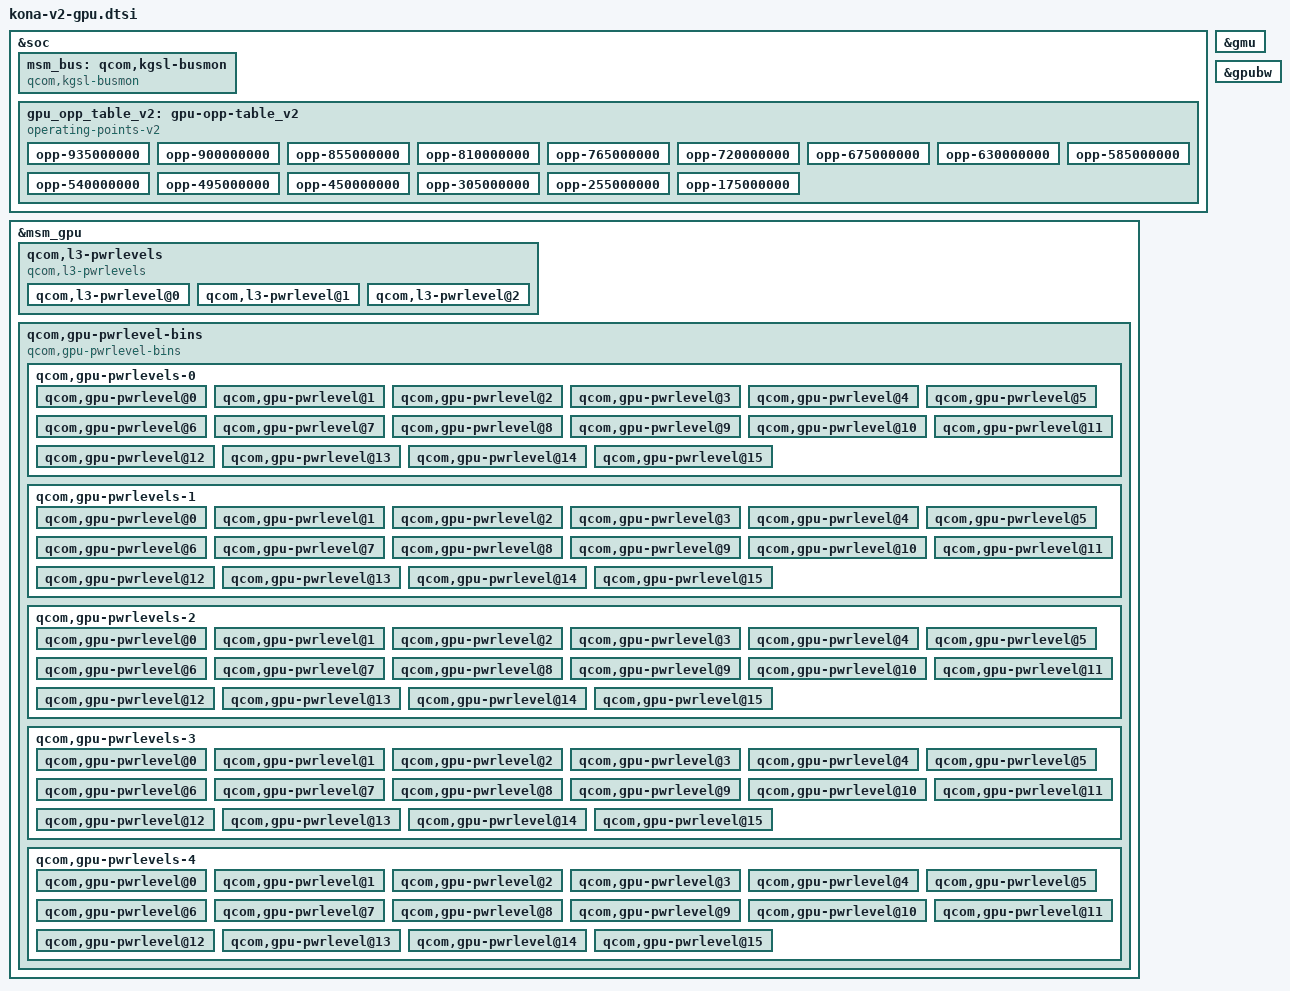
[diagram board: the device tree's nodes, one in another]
&soc {
	msm_bus: qcom,kgsl-busmon {
		label = "kgsl-busmon";
		compatible = "qcom,kgsl-busmon";
		operating-points-v2 = <&gpu_opp_table_v2>;
	};

	gpu_opp_table_v2: gpu-opp-table_v2 {
		compatible = "operating-points-v2";

		opp-935000000 {
			opp-hz = /bits/ 64 <935000000>;
			opp-microvolt = <RPMH_REGULATOR_LEVEL_TURBO_L1>;
		};

		opp-900000000 {
			opp-hz = /bits/ 64 <900000000>;
			opp-microvolt = <RPMH_REGULATOR_LEVEL_TURBO>;
		};

		opp-855000000 {
			opp-hz = /bits/ 64 <855000000>;
			opp-microvolt = <RPMH_REGULATOR_LEVEL_TURBO>;
		};

		opp-810000000 {
			opp-hz = /bits/ 64 <810000000>;
			opp-microvolt = <RPMH_REGULATOR_LEVEL_TURBO>;
		};

		opp-765000000 {
			opp-hz = /bits/ 64 <765000000>;
			opp-microvolt = <RPMH_REGULATOR_LEVEL_NOM_L2>;
		};

		opp-720000000 {
			opp-hz = /bits/ 64 <720000000>;
			opp-microvolt = <RPMH_REGULATOR_LEVEL_NOM_L2>;
		};

		opp-675000000 {
			opp-hz = /bits/ 64 <675000000>;
			opp-microvolt = <RPMH_REGULATOR_LEVEL_NOM_L1>;
		};

		opp-630000000 {
			opp-hz = /bits/ 64 <630000000>;
			opp-microvolt = <RPMH_REGULATOR_LEVEL_NOM_L1>;
		};

		opp-585000000 {
			opp-hz = /bits/ 64 <585000000>;
			opp-microvolt = <RPMH_REGULATOR_LEVEL_NOM>;
		};

		opp-540000000 {
			opp-hz = /bits/ 64 <540000000>;
			opp-microvolt = <RPMH_REGULATOR_LEVEL_NOM>;
		};

		opp-495000000 {
			opp-hz = /bits/ 64 <495000000>;
			opp-microvolt = <RPMH_REGULATOR_LEVEL_SVS_L2>;
		};

		opp-450000000 {
			opp-hz = /bits/ 64 <450000000>;
			opp-microvolt = <RPMH_REGULATOR_LEVEL_SVS_L1>;
		};

		opp-305000000 {
			opp-hz = /bits/ 64 <305000000>;
			opp-microvolt = <RPMH_REGULATOR_LEVEL_SVS>;
		};

		opp-255000000 {
			opp-hz = /bits/ 64 <255000000>;
			opp-microvolt = <RPMH_REGULATOR_LEVEL_SVS>;
		};

		opp-175000000 {
			opp-hz = /bits/ 64 <175000000>;
			opp-microvolt = <RPMH_REGULATOR_LEVEL_LOW_SVS>;
		};
	};
};

&msm_gpu {
	qcom,chipid = <0x06050001>;
	interconnects = <&kona_icc KONA_ICC_GPU_TO_LLCC>,
			<&kona_icc KONA_ICC_GPU_TO_MEM>,
			<&kona_icc KONA_ICC_CPU_TO_GPU_CFG>;
	interconnect-names = "gpu-llcc", "gpu-ddr", "cpu-gpu-cfg";

	/*
	 * Kona V2 keeps ICC BW tables explicit in this override as well so
	 * V2 targets don't depend on base include ordering for ICC-first voting.
	 */
	qcom,gpu-icc-bw-avg-kbps =
		<1 292968 440429 622558 760253 946289 1113281
		 1406250 1968750 2390625 2812500 3515625 4218750 4921875>;
	qcom,gpu-icc-bw-peak-kbps =
		<1 1171875 1761718 2490234 3041015 3785156 4453125
		 5625000 7875000 9562500 11250000 14062500 16875000 19687500>;
	qcom,gpu-cfg-icc-bw-avg-kbps = <1 25>;
	qcom,gpu-cfg-icc-bw-peak-kbps = <1 100>;

	qcom,ca-busy-penalty = <9000>;
	qcom,enable-midframe-timer;
	qcom,wakeup-boost-ms = <60>;
	qcom,wakeup-boost-pwrlevel = <4>;
	qcom,tz-sample-floor = <2500>;
	qcom,tz-min-busy = <550>;
	qcom,tz-busy-ceiling = <28000>;

	/* GPU OPP data */
	operating-points-v2 = <&gpu_opp_table_v2>;

	/delete-property/qcom,initial-pwrlevel;
	/delete-node/qcom,gpu-pwrlevels;
	/delete-node/qcom,l3-pwrlevels;

	/* L3 vote levels tuned for the higher Kona V2 GPU bins */
	qcom,l3-pwrlevels {
		#address-cells = <1>;
		#size-cells = <0>;
		compatible = "qcom,l3-pwrlevels";

		qcom,l3-pwrlevel@0 {
			reg = <0>;
			qcom,l3-freq = <0>;
		};

		qcom,l3-pwrlevel@1 {
			reg = <1>;
			qcom,l3-freq = <1066000000>;
		};

		qcom,l3-pwrlevel@2 {
			reg = <2>;
			qcom,l3-freq = <1612800000>;
		};
	};

	/* Power levels bins */
	qcom,gpu-pwrlevel-bins {
		compatible="qcom,gpu-pwrlevel-bins";
		#address-cells = <1>;
		#size-cells = <0>;

		qcom,gpu-pwrlevels-0 {
			#address-cells = <1>;
			#size-cells = <0>;
			qcom,speed-bin = <0>;
			qcom,initial-pwrlevel = <4>;
			qcom,max-pwrlevel = <1>;

					qcom,gpu-pwrlevel@0 {
								reg = <0>;
								qcom,gpu-freq = <935000000>;
								qcom,bus-freq-ddr7 = <13>;
								qcom,bus-min-ddr7 = <13>;
								qcom,bus-max-ddr7 = <13>;

								qcom,bus-freq-ddr8 = <13>;
								qcom,bus-min-ddr8 = <13>;
								qcom,bus-max-ddr8 = <13>;
							};

							qcom,gpu-pwrlevel@1 {
								reg = <1>;
								qcom,gpu-freq = <900000000>;
								qcom,bus-freq-ddr7 = <13>;
								qcom,bus-min-ddr7 = <13>;
								qcom,bus-max-ddr7 = <13>;

								qcom,bus-freq-ddr8 = <13>;
								qcom,bus-min-ddr8 = <13>;
								qcom,bus-max-ddr8 = <13>;
							};

							qcom,gpu-pwrlevel@2 {
								reg = <2>;
								qcom,gpu-freq = <855000000>;
								qcom,bus-freq-ddr7 = <13>;
								qcom,bus-min-ddr7 = <13>;
								qcom,bus-max-ddr7 = <13>;

								qcom,bus-freq-ddr8 = <13>;
								qcom,bus-min-ddr8 = <13>;
								qcom,bus-max-ddr8 = <13>;
							};

							qcom,gpu-pwrlevel@3 {
								reg = <3>;
								qcom,gpu-freq = <810000000>;
								qcom,bus-freq-ddr7 = <13>;
								qcom,bus-min-ddr7 = <13>;
								qcom,bus-max-ddr7 = <13>;

								qcom,bus-freq-ddr8 = <13>;
								qcom,bus-min-ddr8 = <13>;
								qcom,bus-max-ddr8 = <13>;
							};

							qcom,gpu-pwrlevel@4 {
								reg = <4>;
								qcom,gpu-freq = <765000000>;
								qcom,bus-freq-ddr7 = <12>;
								qcom,bus-min-ddr7 = <12>;
								qcom,bus-max-ddr7 = <12>;

								qcom,bus-freq-ddr8 = <12>;
								qcom,bus-min-ddr8 = <12>;
								qcom,bus-max-ddr8 = <12>;
							};

							qcom,gpu-pwrlevel@5 {
								reg = <5>;
								qcom,gpu-freq = <720000000>;
								qcom,bus-freq-ddr7 = <12>;
								qcom,bus-min-ddr7 = <12>;
								qcom,bus-max-ddr7 = <12>;

								qcom,bus-freq-ddr8 = <12>;
								qcom,bus-min-ddr8 = <12>;
								qcom,bus-max-ddr8 = <12>;
							};

							qcom,gpu-pwrlevel@6 {
								reg = <6>;
								qcom,gpu-freq = <675000000>;
								qcom,bus-freq-ddr7 = <11>;
								qcom,bus-min-ddr7 = <11>;
								qcom,bus-max-ddr7 = <11>;

								qcom,bus-freq-ddr8 = <11>;
								qcom,bus-min-ddr8 = <11>;
								qcom,bus-max-ddr8 = <11>;
							};

							qcom,gpu-pwrlevel@7 {
								reg = <7>;
								qcom,gpu-freq = <630000000>;
								qcom,bus-freq-ddr7 = <11>;
								qcom,bus-min-ddr7 = <11>;
								qcom,bus-max-ddr7 = <11>;

								qcom,bus-freq-ddr8 = <11>;
								qcom,bus-min-ddr8 = <11>;
								qcom,bus-max-ddr8 = <11>;
							};

							qcom,gpu-pwrlevel@8 {
								reg = <8>;
								qcom,gpu-freq = <585000000>;
								qcom,bus-freq-ddr7 = <10>;
								qcom,bus-min-ddr7 = <10>;
								qcom,bus-max-ddr7 = <10>;

								qcom,bus-freq-ddr8 = <10>;
								qcom,bus-min-ddr8 = <10>;
								qcom,bus-max-ddr8 = <10>;
							};

							qcom,gpu-pwrlevel@9 {
								reg = <9>;
								qcom,gpu-freq = <540000000>;
								qcom,bus-freq-ddr7 = <10>;
								qcom,bus-min-ddr7 = <10>;
								qcom,bus-max-ddr7 = <10>;

								qcom,bus-freq-ddr8 = <10>;
								qcom,bus-min-ddr8 = <10>;
								qcom,bus-max-ddr8 = <10>;
							};

							qcom,gpu-pwrlevel@10 {
								reg = <10>;
								qcom,gpu-freq = <495000000>;
								qcom,bus-freq-ddr7 = <9>;
								qcom,bus-min-ddr7 = <9>;
								qcom,bus-max-ddr7 = <9>;

								qcom,bus-freq-ddr8 = <9>;
								qcom,bus-min-ddr8 = <9>;
								qcom,bus-max-ddr8 = <9>;
							};

							qcom,gpu-pwrlevel@11 {
								reg = <11>;
								qcom,gpu-freq = <450000000>;
								qcom,bus-freq-ddr7 = <8>;
								qcom,bus-min-ddr7 = <8>;
								qcom,bus-max-ddr7 = <8>;

								qcom,bus-freq-ddr8 = <8>;
								qcom,bus-min-ddr8 = <8>;
								qcom,bus-max-ddr8 = <8>;
							};

							qcom,gpu-pwrlevel@12 {
								reg = <12>;
								qcom,gpu-freq = <305000000>;
								qcom,bus-freq-ddr7 = <7>;
								qcom,bus-min-ddr7 = <7>;
								qcom,bus-max-ddr7 = <7>;

								qcom,bus-freq-ddr8 = <7>;
								qcom,bus-min-ddr8 = <7>;
								qcom,bus-max-ddr8 = <7>;
							};

							qcom,gpu-pwrlevel@13 {
								reg = <13>;
								qcom,gpu-freq = <255000000>;
								qcom,bus-freq-ddr7 = <5>;
								qcom,bus-min-ddr7 = <5>;
								qcom,bus-max-ddr7 = <5>;

								qcom,bus-freq-ddr8 = <5>;
								qcom,bus-min-ddr8 = <5>;
								qcom,bus-max-ddr8 = <5>;
							};

							qcom,gpu-pwrlevel@14 {
								reg = <14>;
								qcom,gpu-freq = <175000000>;
								qcom,bus-freq-ddr7 = <3>;
								qcom,bus-min-ddr7 = <3>;
								qcom,bus-max-ddr7 = <3>;

								qcom,bus-freq-ddr8 = <3>;
								qcom,bus-min-ddr8 = <3>;
								qcom,bus-max-ddr8 = <3>;
							};

							qcom,gpu-pwrlevel@15 {
								reg = <15>;
								qcom,gpu-freq = <0>;
								qcom,bus-freq = <0>;
								qcom,bus-min = <0>;
								qcom,bus-max = <0>;
							};
		};

		qcom,gpu-pwrlevels-1 {
			#address-cells = <1>;
			#size-cells = <0>;
			qcom,speed-bin = <1>;
			qcom,initial-pwrlevel = <4>;
			qcom,max-pwrlevel = <1>;

					qcom,gpu-pwrlevel@0 {
								reg = <0>;
								qcom,gpu-freq = <935000000>;
								qcom,bus-freq-ddr7 = <13>;
								qcom,bus-min-ddr7 = <13>;
								qcom,bus-max-ddr7 = <13>;

								qcom,bus-freq-ddr8 = <13>;
								qcom,bus-min-ddr8 = <13>;
								qcom,bus-max-ddr8 = <13>;
							};

							qcom,gpu-pwrlevel@1 {
								reg = <1>;
								qcom,gpu-freq = <900000000>;
								qcom,bus-freq-ddr7 = <13>;
								qcom,bus-min-ddr7 = <13>;
								qcom,bus-max-ddr7 = <13>;

								qcom,bus-freq-ddr8 = <13>;
								qcom,bus-min-ddr8 = <13>;
								qcom,bus-max-ddr8 = <13>;
							};

							qcom,gpu-pwrlevel@2 {
								reg = <2>;
								qcom,gpu-freq = <855000000>;
								qcom,bus-freq-ddr7 = <13>;
								qcom,bus-min-ddr7 = <13>;
								qcom,bus-max-ddr7 = <13>;

								qcom,bus-freq-ddr8 = <13>;
								qcom,bus-min-ddr8 = <13>;
								qcom,bus-max-ddr8 = <13>;
							};

							qcom,gpu-pwrlevel@3 {
								reg = <3>;
								qcom,gpu-freq = <810000000>;
								qcom,bus-freq-ddr7 = <13>;
								qcom,bus-min-ddr7 = <13>;
								qcom,bus-max-ddr7 = <13>;

								qcom,bus-freq-ddr8 = <13>;
								qcom,bus-min-ddr8 = <13>;
								qcom,bus-max-ddr8 = <13>;
							};

							qcom,gpu-pwrlevel@4 {
								reg = <4>;
								qcom,gpu-freq = <765000000>;
								qcom,bus-freq-ddr7 = <12>;
								qcom,bus-min-ddr7 = <12>;
								qcom,bus-max-ddr7 = <12>;

								qcom,bus-freq-ddr8 = <12>;
								qcom,bus-min-ddr8 = <12>;
								qcom,bus-max-ddr8 = <12>;
							};

							qcom,gpu-pwrlevel@5 {
								reg = <5>;
								qcom,gpu-freq = <720000000>;
								qcom,bus-freq-ddr7 = <12>;
								qcom,bus-min-ddr7 = <12>;
								qcom,bus-max-ddr7 = <12>;

								qcom,bus-freq-ddr8 = <12>;
								qcom,bus-min-ddr8 = <12>;
								qcom,bus-max-ddr8 = <12>;
							};

							qcom,gpu-pwrlevel@6 {
								reg = <6>;
								qcom,gpu-freq = <675000000>;
								qcom,bus-freq-ddr7 = <11>;
								qcom,bus-min-ddr7 = <11>;
								qcom,bus-max-ddr7 = <11>;

								qcom,bus-freq-ddr8 = <11>;
								qcom,bus-min-ddr8 = <11>;
								qcom,bus-max-ddr8 = <11>;
							};

							qcom,gpu-pwrlevel@7 {
								reg = <7>;
								qcom,gpu-freq = <630000000>;
								qcom,bus-freq-ddr7 = <11>;
								qcom,bus-min-ddr7 = <11>;
								qcom,bus-max-ddr7 = <11>;

								qcom,bus-freq-ddr8 = <11>;
								qcom,bus-min-ddr8 = <11>;
								qcom,bus-max-ddr8 = <11>;
							};

							qcom,gpu-pwrlevel@8 {
								reg = <8>;
								qcom,gpu-freq = <585000000>;
								qcom,bus-freq-ddr7 = <10>;
								qcom,bus-min-ddr7 = <10>;
								qcom,bus-max-ddr7 = <10>;

								qcom,bus-freq-ddr8 = <10>;
								qcom,bus-min-ddr8 = <10>;
								qcom,bus-max-ddr8 = <10>;
							};

							qcom,gpu-pwrlevel@9 {
								reg = <9>;
								qcom,gpu-freq = <540000000>;
								qcom,bus-freq-ddr7 = <10>;
								qcom,bus-min-ddr7 = <10>;
								qcom,bus-max-ddr7 = <10>;

								qcom,bus-freq-ddr8 = <10>;
								qcom,bus-min-ddr8 = <10>;
								qcom,bus-max-ddr8 = <10>;
							};

							qcom,gpu-pwrlevel@10 {
								reg = <10>;
								qcom,gpu-freq = <495000000>;
								qcom,bus-freq-ddr7 = <9>;
								qcom,bus-min-ddr7 = <9>;
								qcom,bus-max-ddr7 = <9>;

								qcom,bus-freq-ddr8 = <9>;
								qcom,bus-min-ddr8 = <9>;
								qcom,bus-max-ddr8 = <9>;
							};

							qcom,gpu-pwrlevel@11 {
								reg = <11>;
								qcom,gpu-freq = <450000000>;
								qcom,bus-freq-ddr7 = <8>;
								qcom,bus-min-ddr7 = <8>;
								qcom,bus-max-ddr7 = <8>;

								qcom,bus-freq-ddr8 = <8>;
								qcom,bus-min-ddr8 = <8>;
								qcom,bus-max-ddr8 = <8>;
							};

							qcom,gpu-pwrlevel@12 {
								reg = <12>;
								qcom,gpu-freq = <305000000>;
								qcom,bus-freq-ddr7 = <7>;
								qcom,bus-min-ddr7 = <7>;
								qcom,bus-max-ddr7 = <7>;

								qcom,bus-freq-ddr8 = <7>;
								qcom,bus-min-ddr8 = <7>;
								qcom,bus-max-ddr8 = <7>;
							};

							qcom,gpu-pwrlevel@13 {
								reg = <13>;
								qcom,gpu-freq = <255000000>;
								qcom,bus-freq-ddr7 = <5>;
								qcom,bus-min-ddr7 = <5>;
								qcom,bus-max-ddr7 = <5>;

								qcom,bus-freq-ddr8 = <5>;
								qcom,bus-min-ddr8 = <5>;
								qcom,bus-max-ddr8 = <5>;
							};

							qcom,gpu-pwrlevel@14 {
								reg = <14>;
								qcom,gpu-freq = <175000000>;
								qcom,bus-freq-ddr7 = <3>;
								qcom,bus-min-ddr7 = <3>;
								qcom,bus-max-ddr7 = <3>;

								qcom,bus-freq-ddr8 = <3>;
								qcom,bus-min-ddr8 = <3>;
								qcom,bus-max-ddr8 = <3>;
							};

							qcom,gpu-pwrlevel@15 {
								reg = <15>;
								qcom,gpu-freq = <0>;
								qcom,bus-freq = <0>;
								qcom,bus-min = <0>;
								qcom,bus-max = <0>;
							};
		};

		qcom,gpu-pwrlevels-2 {
			#address-cells = <1>;
			#size-cells = <0>;
			qcom,speed-bin = <3>;
			qcom,initial-pwrlevel = <4>;
			qcom,max-pwrlevel = <1>;

							qcom,gpu-pwrlevel@0 {
								reg = <0>;
								qcom,gpu-freq = <935000000>;
								qcom,bus-freq-ddr7 = <13>;
								qcom,bus-min-ddr7 = <13>;
								qcom,bus-max-ddr7 = <13>;

								qcom,bus-freq-ddr8 = <13>;
								qcom,bus-min-ddr8 = <13>;
								qcom,bus-max-ddr8 = <13>;
							};

							qcom,gpu-pwrlevel@1 {
								reg = <1>;
								qcom,gpu-freq = <900000000>;
								qcom,bus-freq-ddr7 = <13>;
								qcom,bus-min-ddr7 = <13>;
								qcom,bus-max-ddr7 = <13>;

								qcom,bus-freq-ddr8 = <13>;
								qcom,bus-min-ddr8 = <13>;
								qcom,bus-max-ddr8 = <13>;
							};

							qcom,gpu-pwrlevel@2 {
								reg = <2>;
								qcom,gpu-freq = <855000000>;
								qcom,bus-freq-ddr7 = <13>;
								qcom,bus-min-ddr7 = <13>;
								qcom,bus-max-ddr7 = <13>;

								qcom,bus-freq-ddr8 = <13>;
								qcom,bus-min-ddr8 = <13>;
								qcom,bus-max-ddr8 = <13>;
							};

							qcom,gpu-pwrlevel@3 {
								reg = <3>;
								qcom,gpu-freq = <810000000>;
								qcom,bus-freq-ddr7 = <13>;
								qcom,bus-min-ddr7 = <13>;
								qcom,bus-max-ddr7 = <13>;

								qcom,bus-freq-ddr8 = <13>;
								qcom,bus-min-ddr8 = <13>;
								qcom,bus-max-ddr8 = <13>;
							};

							qcom,gpu-pwrlevel@4 {
								reg = <4>;
								qcom,gpu-freq = <765000000>;
								qcom,bus-freq-ddr7 = <12>;
								qcom,bus-min-ddr7 = <12>;
								qcom,bus-max-ddr7 = <12>;

								qcom,bus-freq-ddr8 = <12>;
								qcom,bus-min-ddr8 = <12>;
								qcom,bus-max-ddr8 = <12>;
							};

							qcom,gpu-pwrlevel@5 {
								reg = <5>;
								qcom,gpu-freq = <720000000>;
								qcom,bus-freq-ddr7 = <12>;
								qcom,bus-min-ddr7 = <12>;
								qcom,bus-max-ddr7 = <12>;

								qcom,bus-freq-ddr8 = <12>;
								qcom,bus-min-ddr8 = <12>;
								qcom,bus-max-ddr8 = <12>;
							};

							qcom,gpu-pwrlevel@6 {
								reg = <6>;
								qcom,gpu-freq = <675000000>;
								qcom,bus-freq-ddr7 = <11>;
								qcom,bus-min-ddr7 = <11>;
								qcom,bus-max-ddr7 = <11>;

								qcom,bus-freq-ddr8 = <11>;
								qcom,bus-min-ddr8 = <11>;
								qcom,bus-max-ddr8 = <11>;
							};

							qcom,gpu-pwrlevel@7 {
								reg = <7>;
								qcom,gpu-freq = <630000000>;
								qcom,bus-freq-ddr7 = <11>;
								qcom,bus-min-ddr7 = <11>;
								qcom,bus-max-ddr7 = <11>;

								qcom,bus-freq-ddr8 = <11>;
								qcom,bus-min-ddr8 = <11>;
								qcom,bus-max-ddr8 = <11>;
							};

							qcom,gpu-pwrlevel@8 {
								reg = <8>;
								qcom,gpu-freq = <585000000>;
								qcom,bus-freq-ddr7 = <10>;
								qcom,bus-min-ddr7 = <10>;
								qcom,bus-max-ddr7 = <10>;

								qcom,bus-freq-ddr8 = <10>;
								qcom,bus-min-ddr8 = <10>;
								qcom,bus-max-ddr8 = <10>;
							};

							qcom,gpu-pwrlevel@9 {
								reg = <9>;
								qcom,gpu-freq = <540000000>;
								qcom,bus-freq-ddr7 = <10>;
								qcom,bus-min-ddr7 = <10>;
								qcom,bus-max-ddr7 = <10>;

								qcom,bus-freq-ddr8 = <10>;
								qcom,bus-min-ddr8 = <10>;
								qcom,bus-max-ddr8 = <10>;
							};

							qcom,gpu-pwrlevel@10 {
								reg = <10>;
								qcom,gpu-freq = <495000000>;
								qcom,bus-freq-ddr7 = <9>;
								qcom,bus-min-ddr7 = <9>;
								qcom,bus-max-ddr7 = <9>;

								qcom,bus-freq-ddr8 = <9>;
								qcom,bus-min-ddr8 = <9>;
								qcom,bus-max-ddr8 = <9>;
							};

							qcom,gpu-pwrlevel@11 {
								reg = <11>;
								qcom,gpu-freq = <450000000>;
								qcom,bus-freq-ddr7 = <8>;
								qcom,bus-min-ddr7 = <8>;
								qcom,bus-max-ddr7 = <8>;

								qcom,bus-freq-ddr8 = <8>;
								qcom,bus-min-ddr8 = <8>;
								qcom,bus-max-ddr8 = <8>;
							};

							qcom,gpu-pwrlevel@12 {
								reg = <12>;
								qcom,gpu-freq = <305000000>;
								qcom,bus-freq-ddr7 = <7>;
								qcom,bus-min-ddr7 = <7>;
								qcom,bus-max-ddr7 = <7>;

								qcom,bus-freq-ddr8 = <7>;
								qcom,bus-min-ddr8 = <7>;
								qcom,bus-max-ddr8 = <7>;
							};

							qcom,gpu-pwrlevel@13 {
								reg = <13>;
								qcom,gpu-freq = <255000000>;
								qcom,bus-freq-ddr7 = <5>;
								qcom,bus-min-ddr7 = <5>;
								qcom,bus-max-ddr7 = <5>;

								qcom,bus-freq-ddr8 = <5>;
								qcom,bus-min-ddr8 = <5>;
								qcom,bus-max-ddr8 = <5>;
							};

							qcom,gpu-pwrlevel@14 {
								reg = <14>;
								qcom,gpu-freq = <175000000>;
								qcom,bus-freq-ddr7 = <3>;
								qcom,bus-min-ddr7 = <3>;
								qcom,bus-max-ddr7 = <3>;

								qcom,bus-freq-ddr8 = <3>;
								qcom,bus-min-ddr8 = <3>;
								qcom,bus-max-ddr8 = <3>;
							};

							qcom,gpu-pwrlevel@15 {
								reg = <15>;
								qcom,gpu-freq = <0>;
								qcom,bus-freq = <0>;
								qcom,bus-min = <0>;
								qcom,bus-max = <0>;
							};
		};

		qcom,gpu-pwrlevels-3 {
			#address-cells = <1>;
			#size-cells = <0>;
			qcom,speed-bin = <2>;
			qcom,initial-pwrlevel = <4>;
			qcom,max-pwrlevel = <1>;

					qcom,gpu-pwrlevel@0 {
								reg = <0>;
								qcom,gpu-freq = <935000000>;
								qcom,bus-freq-ddr7 = <13>;
								qcom,bus-min-ddr7 = <13>;
								qcom,bus-max-ddr7 = <13>;

								qcom,bus-freq-ddr8 = <13>;
								qcom,bus-min-ddr8 = <13>;
								qcom,bus-max-ddr8 = <13>;
							};

							qcom,gpu-pwrlevel@1 {
								reg = <1>;
								qcom,gpu-freq = <900000000>;
								qcom,bus-freq-ddr7 = <13>;
								qcom,bus-min-ddr7 = <13>;
								qcom,bus-max-ddr7 = <13>;

								qcom,bus-freq-ddr8 = <13>;
								qcom,bus-min-ddr8 = <13>;
								qcom,bus-max-ddr8 = <13>;
							};

							qcom,gpu-pwrlevel@2 {
								reg = <2>;
								qcom,gpu-freq = <855000000>;
								qcom,bus-freq-ddr7 = <13>;
								qcom,bus-min-ddr7 = <13>;
								qcom,bus-max-ddr7 = <13>;

								qcom,bus-freq-ddr8 = <13>;
								qcom,bus-min-ddr8 = <13>;
								qcom,bus-max-ddr8 = <13>;
							};

							qcom,gpu-pwrlevel@3 {
								reg = <3>;
								qcom,gpu-freq = <810000000>;
								qcom,bus-freq-ddr7 = <13>;
								qcom,bus-min-ddr7 = <13>;
								qcom,bus-max-ddr7 = <13>;

								qcom,bus-freq-ddr8 = <13>;
								qcom,bus-min-ddr8 = <13>;
								qcom,bus-max-ddr8 = <13>;
							};

							qcom,gpu-pwrlevel@4 {
								reg = <4>;
								qcom,gpu-freq = <765000000>;
								qcom,bus-freq-ddr7 = <12>;
								qcom,bus-min-ddr7 = <12>;
								qcom,bus-max-ddr7 = <12>;

								qcom,bus-freq-ddr8 = <12>;
								qcom,bus-min-ddr8 = <12>;
								qcom,bus-max-ddr8 = <12>;
							};

							qcom,gpu-pwrlevel@5 {
								reg = <5>;
								qcom,gpu-freq = <720000000>;
								qcom,bus-freq-ddr7 = <12>;
								qcom,bus-min-ddr7 = <12>;
								qcom,bus-max-ddr7 = <12>;

								qcom,bus-freq-ddr8 = <12>;
								qcom,bus-min-ddr8 = <12>;
								qcom,bus-max-ddr8 = <12>;
							};

							qcom,gpu-pwrlevel@6 {
								reg = <6>;
								qcom,gpu-freq = <675000000>;
								qcom,bus-freq-ddr7 = <11>;
								qcom,bus-min-ddr7 = <11>;
								qcom,bus-max-ddr7 = <11>;

								qcom,bus-freq-ddr8 = <11>;
								qcom,bus-min-ddr8 = <11>;
								qcom,bus-max-ddr8 = <11>;
							};

							qcom,gpu-pwrlevel@7 {
								reg = <7>;
								qcom,gpu-freq = <630000000>;
								qcom,bus-freq-ddr7 = <11>;
								qcom,bus-min-ddr7 = <11>;
								qcom,bus-max-ddr7 = <11>;

								qcom,bus-freq-ddr8 = <11>;
								qcom,bus-min-ddr8 = <11>;
								qcom,bus-max-ddr8 = <11>;
							};

							qcom,gpu-pwrlevel@8 {
								reg = <8>;
								qcom,gpu-freq = <585000000>;
								qcom,bus-freq-ddr7 = <10>;
								qcom,bus-min-ddr7 = <10>;
								qcom,bus-max-ddr7 = <10>;

								qcom,bus-freq-ddr8 = <10>;
								qcom,bus-min-ddr8 = <10>;
								qcom,bus-max-ddr8 = <10>;
							};

							qcom,gpu-pwrlevel@9 {
								reg = <9>;
								qcom,gpu-freq = <540000000>;
								qcom,bus-freq-ddr7 = <10>;
								qcom,bus-min-ddr7 = <10>;
								qcom,bus-max-ddr7 = <10>;

								qcom,bus-freq-ddr8 = <10>;
								qcom,bus-min-ddr8 = <10>;
								qcom,bus-max-ddr8 = <10>;
							};

							qcom,gpu-pwrlevel@10 {
								reg = <10>;
								qcom,gpu-freq = <495000000>;
								qcom,bus-freq-ddr7 = <9>;
								qcom,bus-min-ddr7 = <9>;
								qcom,bus-max-ddr7 = <9>;

								qcom,bus-freq-ddr8 = <9>;
								qcom,bus-min-ddr8 = <9>;
								qcom,bus-max-ddr8 = <9>;
							};

							qcom,gpu-pwrlevel@11 {
								reg = <11>;
								qcom,gpu-freq = <450000000>;
								qcom,bus-freq-ddr7 = <8>;
								qcom,bus-min-ddr7 = <8>;
								qcom,bus-max-ddr7 = <8>;

								qcom,bus-freq-ddr8 = <8>;
								qcom,bus-min-ddr8 = <8>;
								qcom,bus-max-ddr8 = <8>;
							};

							qcom,gpu-pwrlevel@12 {
								reg = <12>;
								qcom,gpu-freq = <305000000>;
								qcom,bus-freq-ddr7 = <7>;
								qcom,bus-min-ddr7 = <7>;
								qcom,bus-max-ddr7 = <7>;

								qcom,bus-freq-ddr8 = <7>;
								qcom,bus-min-ddr8 = <7>;
								qcom,bus-max-ddr8 = <7>;
							};

							qcom,gpu-pwrlevel@13 {
								reg = <13>;
								qcom,gpu-freq = <255000000>;
								qcom,bus-freq-ddr7 = <5>;
								qcom,bus-min-ddr7 = <5>;
								qcom,bus-max-ddr7 = <5>;

								qcom,bus-freq-ddr8 = <5>;
								qcom,bus-min-ddr8 = <5>;
								qcom,bus-max-ddr8 = <5>;
							};

							qcom,gpu-pwrlevel@14 {
								reg = <14>;
								qcom,gpu-freq = <175000000>;
								qcom,bus-freq-ddr7 = <3>;
								qcom,bus-min-ddr7 = <3>;
								qcom,bus-max-ddr7 = <3>;

								qcom,bus-freq-ddr8 = <3>;
								qcom,bus-min-ddr8 = <3>;
								qcom,bus-max-ddr8 = <3>;
							};

							qcom,gpu-pwrlevel@15 {
								reg = <15>;
								qcom,gpu-freq = <0>;
								qcom,bus-freq = <0>;
								qcom,bus-min = <0>;
								qcom,bus-max = <0>;
							};
		};

		qcom,gpu-pwrlevels-4 {
			#address-cells = <1>;
			#size-cells = <0>;
			qcom,speed-bin = <4>;
			qcom,initial-pwrlevel = <4>;
			qcom,max-pwrlevel = <1>;

					qcom,gpu-pwrlevel@0 {
								reg = <0>;
								qcom,gpu-freq = <935000000>;
								qcom,bus-freq-ddr7 = <13>;
								qcom,bus-min-ddr7 = <13>;
								qcom,bus-max-ddr7 = <13>;

								qcom,bus-freq-ddr8 = <13>;
								qcom,bus-min-ddr8 = <13>;
								qcom,bus-max-ddr8 = <13>;
							};

							qcom,gpu-pwrlevel@1 {
								reg = <1>;
								qcom,gpu-freq = <900000000>;
								qcom,bus-freq-ddr7 = <13>;
								qcom,bus-min-ddr7 = <13>;
								qcom,bus-max-ddr7 = <13>;

								qcom,bus-freq-ddr8 = <13>;
								qcom,bus-min-ddr8 = <13>;
								qcom,bus-max-ddr8 = <13>;
							};

							qcom,gpu-pwrlevel@2 {
								reg = <2>;
								qcom,gpu-freq = <855000000>;
								qcom,bus-freq-ddr7 = <13>;
								qcom,bus-min-ddr7 = <13>;
								qcom,bus-max-ddr7 = <13>;

								qcom,bus-freq-ddr8 = <13>;
								qcom,bus-min-ddr8 = <13>;
								qcom,bus-max-ddr8 = <13>;
							};

							qcom,gpu-pwrlevel@3 {
								reg = <3>;
								qcom,gpu-freq = <810000000>;
								qcom,bus-freq-ddr7 = <13>;
								qcom,bus-min-ddr7 = <13>;
								qcom,bus-max-ddr7 = <13>;

								qcom,bus-freq-ddr8 = <13>;
								qcom,bus-min-ddr8 = <13>;
								qcom,bus-max-ddr8 = <13>;
							};

							qcom,gpu-pwrlevel@4 {
								reg = <4>;
								qcom,gpu-freq = <765000000>;
								qcom,bus-freq-ddr7 = <12>;
								qcom,bus-min-ddr7 = <12>;
								qcom,bus-max-ddr7 = <12>;

								qcom,bus-freq-ddr8 = <12>;
								qcom,bus-min-ddr8 = <12>;
								qcom,bus-max-ddr8 = <12>;
							};

							qcom,gpu-pwrlevel@5 {
								reg = <5>;
								qcom,gpu-freq = <720000000>;
								qcom,bus-freq-ddr7 = <12>;
								qcom,bus-min-ddr7 = <12>;
								qcom,bus-max-ddr7 = <12>;

								qcom,bus-freq-ddr8 = <12>;
								qcom,bus-min-ddr8 = <12>;
								qcom,bus-max-ddr8 = <12>;
							};

							qcom,gpu-pwrlevel@6 {
								reg = <6>;
								qcom,gpu-freq = <675000000>;
								qcom,bus-freq-ddr7 = <11>;
								qcom,bus-min-ddr7 = <11>;
								qcom,bus-max-ddr7 = <11>;

								qcom,bus-freq-ddr8 = <11>;
								qcom,bus-min-ddr8 = <11>;
								qcom,bus-max-ddr8 = <11>;
							};

							qcom,gpu-pwrlevel@7 {
								reg = <7>;
								qcom,gpu-freq = <630000000>;
								qcom,bus-freq-ddr7 = <11>;
								qcom,bus-min-ddr7 = <11>;
								qcom,bus-max-ddr7 = <11>;

								qcom,bus-freq-ddr8 = <11>;
								qcom,bus-min-ddr8 = <11>;
								qcom,bus-max-ddr8 = <11>;
							};

							qcom,gpu-pwrlevel@8 {
								reg = <8>;
								qcom,gpu-freq = <585000000>;
								qcom,bus-freq-ddr7 = <10>;
								qcom,bus-min-ddr7 = <10>;
								qcom,bus-max-ddr7 = <10>;

								qcom,bus-freq-ddr8 = <10>;
								qcom,bus-min-ddr8 = <10>;
								qcom,bus-max-ddr8 = <10>;
							};

							qcom,gpu-pwrlevel@9 {
								reg = <9>;
								qcom,gpu-freq = <540000000>;
								qcom,bus-freq-ddr7 = <10>;
								qcom,bus-min-ddr7 = <10>;
								qcom,bus-max-ddr7 = <10>;

								qcom,bus-freq-ddr8 = <10>;
								qcom,bus-min-ddr8 = <10>;
								qcom,bus-max-ddr8 = <10>;
							};

							qcom,gpu-pwrlevel@10 {
								reg = <10>;
								qcom,gpu-freq = <495000000>;
								qcom,bus-freq-ddr7 = <9>;
								qcom,bus-min-ddr7 = <9>;
								qcom,bus-max-ddr7 = <9>;

								qcom,bus-freq-ddr8 = <9>;
								qcom,bus-min-ddr8 = <9>;
								qcom,bus-max-ddr8 = <9>;
							};

							qcom,gpu-pwrlevel@11 {
								reg = <11>;
								qcom,gpu-freq = <450000000>;
								qcom,bus-freq-ddr7 = <8>;
								qcom,bus-min-ddr7 = <8>;
								qcom,bus-max-ddr7 = <8>;

								qcom,bus-freq-ddr8 = <8>;
								qcom,bus-min-ddr8 = <8>;
								qcom,bus-max-ddr8 = <8>;
							};

							qcom,gpu-pwrlevel@12 {
								reg = <12>;
								qcom,gpu-freq = <305000000>;
								qcom,bus-freq-ddr7 = <7>;
								qcom,bus-min-ddr7 = <7>;
								qcom,bus-max-ddr7 = <7>;

								qcom,bus-freq-ddr8 = <7>;
								qcom,bus-min-ddr8 = <7>;
								qcom,bus-max-ddr8 = <7>;
							};

							qcom,gpu-pwrlevel@13 {
								reg = <13>;
								qcom,gpu-freq = <255000000>;
								qcom,bus-freq-ddr7 = <5>;
								qcom,bus-min-ddr7 = <5>;
								qcom,bus-max-ddr7 = <5>;

								qcom,bus-freq-ddr8 = <5>;
								qcom,bus-min-ddr8 = <5>;
								qcom,bus-max-ddr8 = <5>;
							};

							qcom,gpu-pwrlevel@14 {
								reg = <14>;
								qcom,gpu-freq = <175000000>;
								qcom,bus-freq-ddr7 = <3>;
								qcom,bus-min-ddr7 = <3>;
								qcom,bus-max-ddr7 = <3>;

								qcom,bus-freq-ddr8 = <3>;
								qcom,bus-min-ddr8 = <3>;
								qcom,bus-max-ddr8 = <3>;
							};

							qcom,gpu-pwrlevel@15 {
								reg = <15>;
								qcom,gpu-freq = <0>;
								qcom,bus-freq = <0>;
								qcom,bus-min = <0>;
								qcom,bus-max = <0>;
							};
		};
	};
};

&gmu {
	interconnects = <&kona_icc KONA_ICC_GMU_TO_LLCC>,
			<&kona_icc KONA_ICC_GMU_TO_MEM>;
	interconnect-names = "gmu-llcc", "gmu-ddr";
	qcom,gmu-freq = <575000000>;
	qcom,gmu-icc-bw-avg-kbps = <1 292968 585937 878906>;
	qcom,gmu-icc-bw-peak-kbps = <1 1171875 2343750 3515625>;
};

&gpubw {
	/*
	 * V2 bins can sustain higher clocks than base A650, but keep the
	 * floor below top DDR/LLCC corners so light GPU work and UI
	 * composition are not pinned at gaming bandwidth all day.
	 */
	qcom,icc-no-split-ab-kbps;
	qcom,icc-boost-percent = <160>;
	qcom,polling-ms = <6>;
	qcom,icc-upscale-percent = <260>;
	qcom,icc-min-avg-kbps = <3515625>;
	qcom,icc-min-peak-kbps = <14062500>;
};
